# WS63 register map
File version: 1.0
CPU: other r0p0, little endian, MPU, FPU, 3 interrupt priority bits
Registers are 32-bit, read-write, reset 0x0 unless marked. A register's access mark holds for its fields unless they carry their own. Offsets are from the block's base; [hi:lo] are bit positions; {n}, {i} and the like mark numbered series; 'fields as' and 'values as' point back to an identical list.

## PKE — Public Key Engine - modular arithmetic accelerator
Base 0x44110000
0x00 PKE_WORK_LEN — PKE work length register
  [31:0] work_len — Operand bit length for modular arithmetic
0x04 PKE_INSTR0 — PKE instruction register 0
  [31:0] instr0 — Instruction code 0 (0=MUL_MOD, 1=ADD_MOD, 2=SUB_MOD)
    0=MUL_MOD (Modular multiplication); 1=ADD_MOD (Modular addition); 2=SUB_MOD (Modular subtraction)
0x08 PKE_INSTR1 — PKE instruction register 1
  [31:0] instr1 — Instruction code 1
0x0C PKE_INSTR_ADDR_LOW — PKE instruction start address low
  [31:0] instr_addr_low — Instruction start address [31:0]
0x10 PKE_INSTR_ADDR_HIG — PKE instruction start address high
  [31:0] instr_addr_hig — Instruction start address high bits
0x14 PKE_INSTR_LEN — PKE instruction length
  [31:0] instr_len — Total instruction length in bytes
0x18 PKE_MASK_RNG_CFG — PKE mask RNG configuration
  [0] mask_rng_cfg — Mask RNG enable: 0=disabled; 1=enabled
0x20 PKE_MONT_PARA0 — PKE Montgomery parameter 0
  [31:0] mont_para0 — Montgomery pre-computed parameter word 0
0x24 PKE_MONT_PARA1 — PKE Montgomery parameter 1
  [31:0] mont_para1 — Montgomery pre-computed parameter word 1
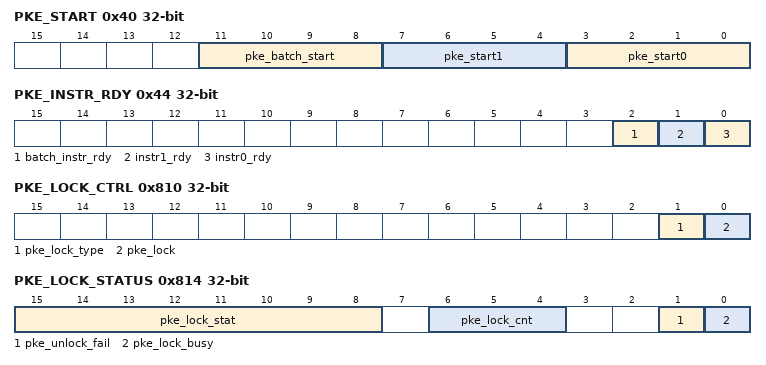
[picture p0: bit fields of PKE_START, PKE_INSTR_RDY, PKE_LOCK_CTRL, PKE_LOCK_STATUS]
0x40 PKE_START — PKE start control register
  [11:8] pke_batch_start wo — Batch start code (write 0x5)
  [7:4] pke_start1 wo — Start code 1 (write 0xA)
    10=StartCode (Must write 0xA to start PKE operation)
  [3:0] pke_start0 wo — Start code 0 (write 0x5 to start)
    5=StartCode (Must write 0x5 to start PKE operation)
0x44 PKE_INSTR_RDY — PKE instruction ready status
  [2] batch_instr_rdy ro — Batch instruction ready
  [1] instr1_rdy ro — Instruction buffer 1 ready
  [0] instr0_rdy ro — Instruction buffer 0 ready
0x48 PKE_BUSY — PKE busy status register
  [0] pke_busy ro — PKE busy: 0=idle; 1=busy
0x4C PKE_NOISE_EN — PKE noise enable register
  [0] noise_en — Side-channel noise enable
0x80 PKE_INT_ENABLE — PKE interrupt enable
  [0] finish_int_enable — Operation finish interrupt enable
0x84 PKE_INT_NOMASK_STATUS — PKE unmasked interrupt status
  [3:0] finish_int_nomask ro — Finish interrupt status (expect 0x5 after completion)
0x8C PKE_ALARM_STATUS
  [3:0] alarm_int ro — Security alarm interrupt
0x90 PKE_FAILURE_FLAG
  [10:0] pke_failure_flag ro — Operation failure status
0xC0 PKE_DRAM_CLR — PKE DRAM clear register
  [0] dram_clr wo — Clear PKE DRAM
0x810 PKE_LOCK_CTRL — PKE lock control register
  [1] pke_lock_type — Lock type: 0=soft; 1=hard
  [0] pke_lock — Lock request
0x814 PKE_LOCK_STATUS
  [15:8] pke_lock_stat ro — Lock status: 0x6A=PCPU; 0x35=AIDSP; 0xA5=TEE; 0xAA=ACPU
  [6:4] pke_lock_cnt ro — Lock count
  [1] pke_unlock_fail ro — Unlock failure flag
  [0] pke_lock_busy ro — Lock busy flag

## KM — Key Management - KLAD key derivation, keyslot locking, RKP root key protection
Base 0x44112000
{0x1000+4i} KL_DATA_IN_{i} (i=0..3) — Key data input word {i}
  [31:0] data — Key data[{32i+31}:{32i}]
0x1010 KL_KEY_ADDR — Key address register
  [9:0] key_addr — Target key slot address
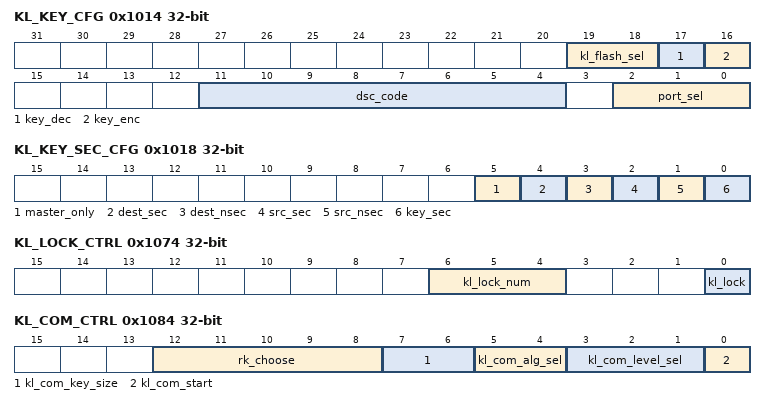
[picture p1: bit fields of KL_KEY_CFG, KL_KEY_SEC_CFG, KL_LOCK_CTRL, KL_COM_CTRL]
0x1014 KL_KEY_CFG — Key configuration register
  [19:18] kl_flash_sel — Flash key source select
  [17] key_dec — Key decrypt enable
  [16] key_enc — Key encrypt enable
  [11:4] dsc_code — Descriptor code
  [2:0] port_sel — Port select
0x1018 KL_KEY_SEC_CFG — Key security configuration
  [5] master_only — Master-only access
  [4] dest_sec — Destination secure
  [3] dest_nsec — Destination non-secure
  [2] src_sec — Source secure: 0=NS; 1=Secure
  [1] src_nsec — Source non-secure: 0=secure; 1=NS
  [0] key_sec — Key security: 0=NS; 1=Secure
0x1030 KL_STATE — KLAD state register
  [31:0] state ro — KLAD processing state
0x1038 KL_ERROR — KLAD error register
  [31:0] error ro — KLAD error code
0x1040 KL_INT_EN — KLAD interrupt enable
  [0] kl_int_en
0x1048 KL_INT — KLAD interrupt status
  [0] kl_int ro — KLAD interrupt flag
0x1074 KL_LOCK_CTRL — KLAD lock control
  [6:4] kl_lock_num — Lock sequence number
  [0] kl_lock wo — Lock request
0x1084 KL_COM_CTRL — KLAD common control
  [12:8] rk_choose — Root key select: 4=USD; 5=SBRK; 6=ABRK; 13=DRK; 18=PSK
  [7:6] kl_com_key_size — Key size select
  [5:4] kl_com_alg_sel — Algorithm select
  [3:1] kl_com_level_sel — Level select
  [0] kl_com_start wo — Common KDF start
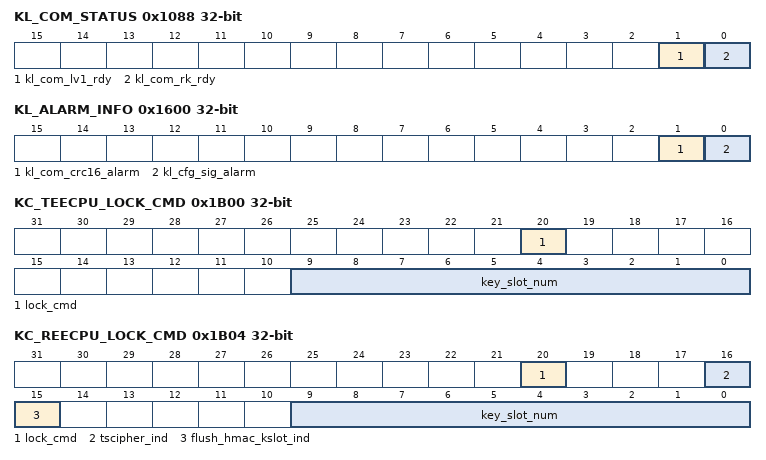
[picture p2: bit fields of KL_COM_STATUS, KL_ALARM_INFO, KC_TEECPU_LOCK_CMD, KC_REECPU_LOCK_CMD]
0x1088 KL_COM_STATUS — KLAD common status
  [1] kl_com_lv1_rdy ro — Level 1 key ready
  [0] kl_com_rk_rdy ro — Root key ready
0x1600 KL_ALARM_INFO — KLAD alarm info register
  [1] kl_com_crc16_alarm ro — Common CRC16 alarm
  [0] kl_cfg_sig_alarm ro — Config signature alarm
0x1B00 KC_TEECPU_LOCK_CMD — TEE CPU keyslot lock command
  [20] lock_cmd wo — Lock command: 0x01=REE; 0x10=TEE; 0x100=PCPU; 0x110=AIDSP
  [9:0] key_slot_num — Key slot number
0x1B04 KC_REECPU_LOCK_CMD — REE CPU keyslot lock command
  [20] lock_cmd wo — Lock command: 1=lock; 0=unlock
  [16] tscipher_ind — TSCipher indicator
  [15] flush_hmac_kslot_ind — Keyslot type: 0=mcipher; 1=HMAC
  [9:0] key_slot_num — Key slot number
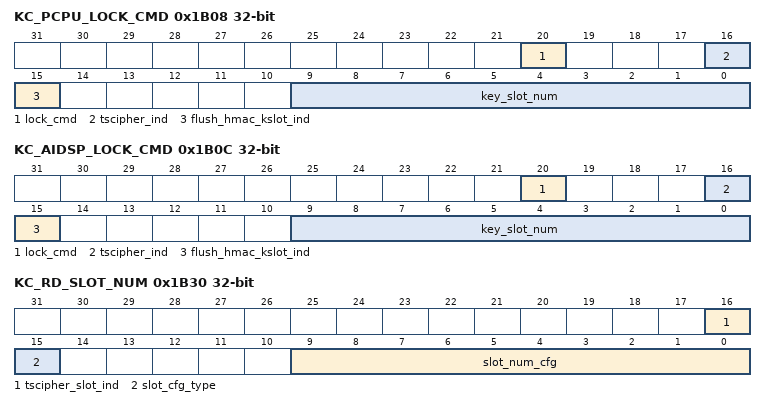
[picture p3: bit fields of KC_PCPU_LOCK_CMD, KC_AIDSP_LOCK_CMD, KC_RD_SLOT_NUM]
0x1B08 KC_PCPU_LOCK_CMD — PCPU keyslot lock command
  fields as KC_REECPU_LOCK_CMD
0x1B0C KC_AIDSP_LOCK_CMD — AIDSP keyslot lock command
  fields as KC_REECPU_LOCK_CMD
0x1B30 KC_RD_SLOT_NUM — Keyslot query slot number selection
  [16] tscipher_slot_ind — TSCipher slot indicator
  [15] slot_cfg_type — Keyslot type: 0=mcipher; 1=HMAC
  [9:0] slot_num_cfg — Slot number to query (0-255)
0x1B34 KC_RD_LOCK_STATUS — Keyslot lock status readback
  [2:0] rd_lock_status ro — Lock status: 0=unlock; 1=REE; 2=TEE; 4=PCPU; 6=AIDSP
